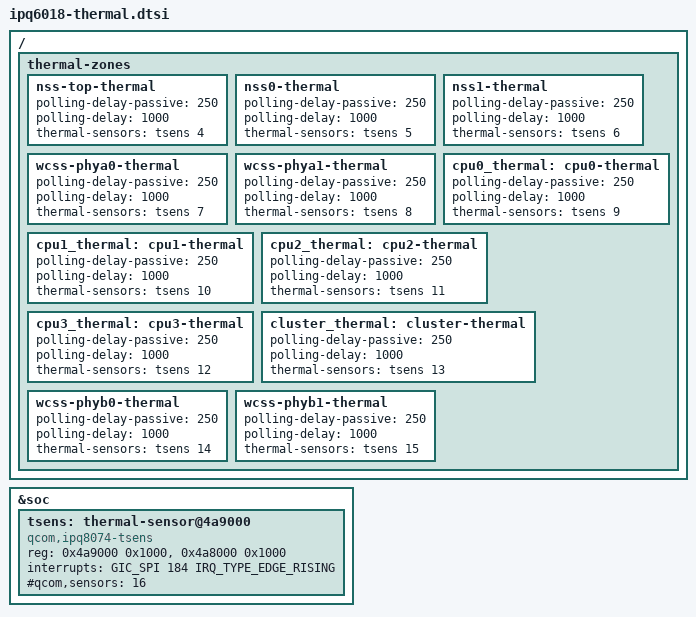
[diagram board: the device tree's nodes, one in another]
/ {
  thermal-zones {
    nss-top-thermal {
			polling-delay-passive = <250>;
			polling-delay = <1000>;

			thermal-sensors = <&tsens 4>;
		};

		nss0-thermal {
			polling-delay-passive = <250>;
			polling-delay = <1000>;

			thermal-sensors = <&tsens 5>;
		};

		nss1-thermal {
			polling-delay-passive = <250>;
			polling-delay = <1000>;

			thermal-sensors = <&tsens 6>;
		};

		wcss-phya0-thermal {
			polling-delay-passive = <250>;
			polling-delay = <1000>;

			thermal-sensors = <&tsens 7>;
		};

		wcss-phya1-thermal {
			polling-delay-passive = <250>;
			polling-delay = <1000>;

			thermal-sensors = <&tsens 8>;
		};

		cpu0_thermal: cpu0-thermal {
			polling-delay-passive = <250>;
			polling-delay = <1000>;

			thermal-sensors = <&tsens 9>;
		};

		cpu1_thermal: cpu1-thermal {
			polling-delay-passive = <250>;
			polling-delay = <1000>;

			thermal-sensors = <&tsens 10>;
		};

		cpu2_thermal: cpu2-thermal {
			polling-delay-passive = <250>;
			polling-delay = <1000>;

			thermal-sensors = <&tsens 11>;
		};

		cpu3_thermal: cpu3-thermal {
			polling-delay-passive = <250>;
			polling-delay = <1000>;

			thermal-sensors = <&tsens 12>;
		};

		cluster_thermal: cluster-thermal {
			polling-delay-passive = <250>;
			polling-delay = <1000>;

			thermal-sensors = <&tsens 13>;
		};

		wcss-phyb0-thermal {
			polling-delay-passive = <250>;
			polling-delay = <1000>;

			thermal-sensors = <&tsens 14>;
		};

		wcss-phyb1-thermal {
			polling-delay-passive = <250>;
			polling-delay = <1000>;

			thermal-sensors = <&tsens 15>;
		};
  };
};

&soc {
  tsens: thermal-sensor@4a9000 {
    compatible = "qcom,ipq8074-tsens";
		reg = <0x4a9000 0x1000>, /* TM */
		      <0x4a8000 0x1000>; /* SROT */
		interrupts = <GIC_SPI 184 IRQ_TYPE_EDGE_RISING>;
    interrupt-names = "combined";
    #qcom,sensors = <16>;
		#thermal-sensor-cells = <1>;
  };
};

